# CY8C5888LTI_LP097 register map
File version: 0.1
Registers are 8-bit, read-write, no defined reset value unless marked. A register's access mark holds for its fields unless they carry their own. Offsets are from the block's base; [hi:lo] are bit positions; {n}, {i} and the like mark numbered series; 'fields as' and 'values as' point back to an identical list.

## resetServoTimer
Base 0x00000000
0x40006474 resetServoTimer_CONTROL_REG

## PC — UART
Base 0x00000000
0x40006428 RX_PC_RX_ADDRESS1 — RX Address1 Register
0x40006438 RX_PC_RX_ADDRESS2 — RX Address2 Register
0x40006448 RX_PC_RX_DATA — RX Data Register
0x40006549 TX_PC_TX_DATA — TX Data Register
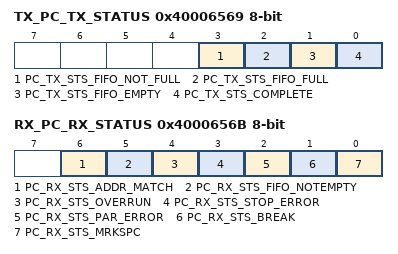
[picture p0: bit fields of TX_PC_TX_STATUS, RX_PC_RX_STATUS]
0x40006569 TX_PC_TX_STATUS — TX status register
  [3] PC_TX_STS_FIFO_NOT_FULL ro, [2] PC_TX_STS_FIFO_FULL ro, [1] PC_TX_STS_FIFO_EMPTY ro, [0] PC_TX_STS_COMPLETE ro
0x4000656B RX_PC_RX_STATUS — RX status register
  [6] PC_RX_STS_ADDR_MATCH ro, [5] PC_RX_STS_FIFO_NOTEMPTY ro, [4] PC_RX_STS_OVERRUN ro, [3] PC_RX_STS_STOP_ERROR ro, [2] PC_RX_STS_PAR_ERROR ro, [1] PC_RX_STS_BREAK ro, [0] PC_RX_STS_MRKSPC ro

## PWM2
Base 0x00000000
0x40006424 PWM2_COMPARE_1 16-bit — UDB.D0 - Assigned Compare1 Value
0x40006434 PWM2_COMPARE_2 16-bit — UDB.D1 - Assigned Compare2 Value
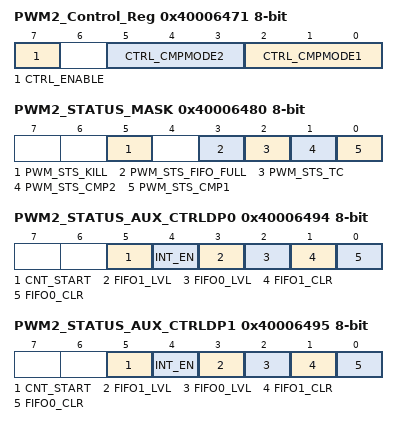
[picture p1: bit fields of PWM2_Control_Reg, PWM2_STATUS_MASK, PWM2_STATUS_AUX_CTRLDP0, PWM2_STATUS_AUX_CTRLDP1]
0x40006471 PWM2_Control_Reg — UDB Control Register - Assigned Control Register Value
  [7] CTRL_ENABLE — Enable the PWM
  [5:3] CTRL_CMPMODE2 — Compare mode 2
  [2:0] CTRL_CMPMODE1 — Compare mode 1
0x40006480 PWM2_STATUS_MASK — UDB Status bits Interrupt Mask Enable Register
  [5] PWM_STS_KILL ro — Enables the Interrupt on Kill
  [3] PWM_STS_FIFO_FULL ro — FIFO Full Status Mask
  [2] PWM_STS_TC ro — Enables the Interrupt on Terminal Count
  [1] PWM_STS_CMP2 ro — Enables the Interrupt on Compare 2
  [0] PWM_STS_CMP1 ro — Enables the Interrupt on Compare 1
0x40006494 PWM2_STATUS_AUX_CTRLDP0 — UDB Auxilliary Control Register
  [5] CNT_START — FIFO0 clear
    0=E_CNT_START0 (Disable counter); 1=E_CNT_START1 (Enable counter)
  [4] INT_EN
    0=E_INT_EN0 (Interrupt disabled); 1=E_INT_EN1 (Interrupt enabled)
  [3] FIFO1_LVL — FIFO level
    0=E_FIFO_LVL_0 (FIFO LVL: input mode: FIFO not full; output mode: FIFO not empty); 1=E_FIFO_LVL_1 (FIFO LVL: input mode: FIFO at least 1/2 empty; output mode: FIFO at least 1/2 full)
  [2] FIFO0_LVL — FIFO level
    values as FIFO1_LVL
  [1] FIFO1_CLR — FIFO1 clear
    0=E_FIFO_CLR_0 (Normal FIFO operation); 1=E_FIFO_CLR_1 (Clear FIFO state)
  [0] FIFO0_CLR — FIFO0 clear
    values as FIFO1_CLR
0x40006495 PWM2_STATUS_AUX_CTRLDP1 — UDB Auxilliary Control Register
  fields as PWM2_STATUS_AUX_CTRLDP0

## ADC_SAR — SAR ADC
Base 0x00000000
0x40004616 SAR_TR0 — SAR trim register
{0x40005908+i} SAR_CSR{i} (i=0..6) — SAR status and control register {i}
0x40005B28 SAR_SW0 — SAR Analog Routing Register 0
{0x40005B28+i} SAR_SW{i} (i=2..4) — SAR Analog Routing Register {i}
0x40005B2E SAR_SW6 — SAR Analog Routing Register 6
0x40005B2F SAR_CLK — SAR Clock Selection Register
0x40005BA2 SAR_WRK 16-bit — SAR working register

## PWM1
Base 0x00000000
0x40006422 PWM1_COMPARE_1 16-bit — UDB.D0 - Assigned Compare1 Value
0x40006432 PWM1_COMPARE_2 16-bit — UDB.D1 - Assigned Compare2 Value
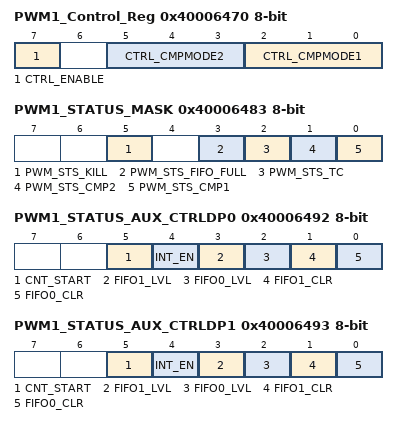
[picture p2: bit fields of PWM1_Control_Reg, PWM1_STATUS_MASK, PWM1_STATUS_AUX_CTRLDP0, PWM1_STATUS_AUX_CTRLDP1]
0x40006470 PWM1_Control_Reg — UDB Control Register - Assigned Control Register Value
  [7] CTRL_ENABLE — Enable the PWM
  [5:3] CTRL_CMPMODE2 — Compare mode 2
  [2:0] CTRL_CMPMODE1 — Compare mode 1
0x40006483 PWM1_STATUS_MASK — UDB Status bits Interrupt Mask Enable Register
  [5] PWM_STS_KILL ro — Enables the Interrupt on Kill
  [3] PWM_STS_FIFO_FULL ro — FIFO Full Status Mask
  [2] PWM_STS_TC ro — Enables the Interrupt on Terminal Count
  [1] PWM_STS_CMP2 ro — Enables the Interrupt on Compare 2
  [0] PWM_STS_CMP1 ro — Enables the Interrupt on Compare 1
0x40006492 PWM1_STATUS_AUX_CTRLDP0 — UDB Auxilliary Control Register
  [5] CNT_START — FIFO0 clear
    0=E_CNT_START0 (Disable counter); 1=E_CNT_START1 (Enable counter)
  [4] INT_EN
    0=E_INT_EN0 (Interrupt disabled); 1=E_INT_EN1 (Interrupt enabled)
  [3] FIFO1_LVL — FIFO level
    0=E_FIFO_LVL_0 (FIFO LVL: input mode: FIFO not full; output mode: FIFO not empty); 1=E_FIFO_LVL_1 (FIFO LVL: input mode: FIFO at least 1/2 empty; output mode: FIFO at least 1/2 full)
  [2] FIFO0_LVL — FIFO level
    values as FIFO1_LVL
  [1] FIFO1_CLR — FIFO1 clear
    0=E_FIFO_CLR_0 (Normal FIFO operation); 1=E_FIFO_CLR_1 (Clear FIFO state)
  [0] FIFO0_CLR — FIFO0 clear
    values as FIFO1_CLR
0x40006493 PWM1_STATUS_AUX_CTRLDP1 — UDB Auxilliary Control Register
  fields as PWM1_STATUS_AUX_CTRLDP0
